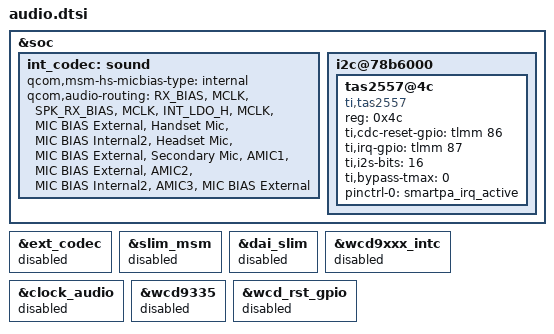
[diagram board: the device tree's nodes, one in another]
&soc {
	int_codec: sound {
		status = "ok";
		qcom,msm-hs-micbias-type = "internal";
		qcom,audio-routing =
			"RX_BIAS", "MCLK",
			"SPK_RX_BIAS", "MCLK",
			"INT_LDO_H", "MCLK",
			"MIC BIAS External", "Handset Mic",
			"MIC BIAS Internal2", "Headset Mic",
			"MIC BIAS External", "Secondary Mic",
			"AMIC1", "MIC BIAS External",
			"AMIC2", "MIC BIAS Internal2",
			"AMIC3", "MIC BIAS External";
		/delete-property/qcom,hdmi-dba-codec-rx;
	};
	i2c@78b6000 {
		status = "okay";
		tas2557@4c {
            compatible = "ti,tas2557";
            reg = <0x4c>;
            ti,cdc-reset-gpio = <&tlmm 86 0>;
            ti,irq-gpio = <&tlmm 87 0x0>;
            ti,i2s-bits = <16>;   /* support 16, 24, 32 */
            ti,bypass-tmax = <0>;   /* 0, not bypass; 1, bypass */
            status = "ok";
			pinctrl-names = "smartpa_irq_active";
			pinctrl-0 = <&smartpa_irq_active>;
		};
	};
};

/* msm8953-audio */
&int_codec {
	/delete-property/msm-vdd-wsa-switch-supply;
	/delete-property/qcom,msm-vdd-wsa-switch-voltage;
	/delete-property/qcom,msm-vdd-wsa-switch-current;
};

&ext_codec {
	status = "disabled";
};

&slim_msm {
	status = "disabled";
};

&dai_slim {
	status = "disabled";
};

&wcd9xxx_intc {
	status = "disabled";
};

&clock_audio {
	status = "disabled";
};

&wcd9335 {
	status = "disabled";
};

&wcd_rst_gpio {
	status = "disabled";
};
